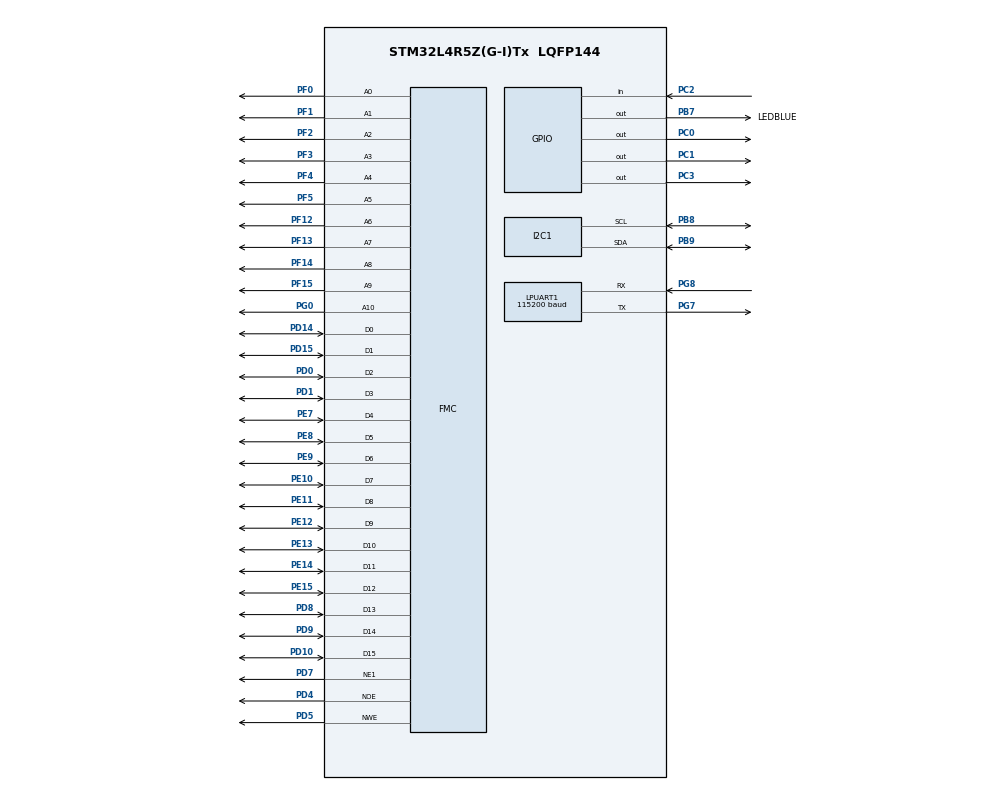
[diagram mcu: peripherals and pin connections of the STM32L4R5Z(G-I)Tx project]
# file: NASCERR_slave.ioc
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FMC.WriteFifo1=FMC_WRITE_FIFO_DISABLE
FMC.WriteFifo2=FMC_WRITE_FIFO_DISABLE
FMC.WriteFifo3=FMC_WRITE_FIFO_DISABLE
FMC.WriteFifo4=FMC_WRITE_FIFO_DISABLE
FMC.WriteOperation1=FMC_WRITE_OPERATION_ENABLE
FREERTOS.Tasks01=defaultTask,24,128,StartDefaultTask,Default,NULL,Dynamic,NULL,NULL
I2C1.OwnAddress=0x55
I2C1.Timing=0x00100D14
IWDG.Prescaler=IWDG_PRESCALER_64
IWDG.Reload=500
LPUART1.BaudRate=115200
LPUART1.WordLength=UART_WORDLENGTH_8B
Mcu.Family=STM32L4
Mcu.Name=STM32L4R5Z(G-I)Tx
Mcu.Package=LQFP144
NVIC.I2C1_ER_IRQn=true\:5\:0\:false\:false\:true\:true\:true\:true\:true
NVIC.I2C1_EV_IRQn=true\:5\:0\:false\:false\:true\:true\:true\:true\:true
NVIC.PriorityGroup=NVIC_PRIORITYGROUP_4
PB7.GPIO_Label=LEDBLUE
PB7.Signal=GPIO_Output
PB8.GPIO_Pu=GPIO_PULLUP
PB8.Mode=I2C
PB8.Signal=I2C1_SCL
PB9.GPIO_Pu=GPIO_PULLUP
PB9.Mode=I2C
PB9.Signal=I2C1_SDA
PC0.Signal=GPIO_Output
PC1.Signal=GPIO_Output
PC2.GPIO_PuPd=GPIO_PULLUP
PC2.Signal=GPIO_Input
PC3.GPIO_PuPd=GPIO_PULLDOWN
PC3.Signal=GPIO_Output
PD0.Signal=FMC_D2_DA2
PD1.Signal=FMC_D3_DA3
PD10.Signal=FMC_D15_DA15
PD14.Signal=FMC_D0_DA0
PD15.Signal=FMC_D1_DA1
PD4.Signal=FMC_NOE
PD5.Signal=FMC_NWE
PD7.Mode=NorPsramChipSelect1_1
PD7.Signal=FMC_NE1
PD8.Signal=FMC_D13_DA13
PD9.Signal=FMC_D14_DA14
PE10.Signal=FMC_D7_DA7
PE11.Signal=FMC_D8_DA8
PE12.Signal=FMC_D9_DA9
PE13.Signal=FMC_D10_DA10
PE14.Signal=FMC_D11_DA11
PE15.Signal=FMC_D12_DA12
PE7.Signal=FMC_D4_DA4
PE8.Signal=FMC_D5_DA5
PE9.Signal=FMC_D6_DA6
PF0.Signal=FMC_A0
PF1.Signal=FMC_A1
PF12.Signal=FMC_A6
PF13.Signal=FMC_A7
PF14.Signal=FMC_A8
PF15.Signal=FMC_A9
PF2.Signal=FMC_A2
PF3.Signal=FMC_A3
PF4.Signal=FMC_A4
PF5.Signal=FMC_A5
PG0.Signal=FMC_A10
PG7.Mode=Asynchronous
PG7.Signal=LPUART1_TX
PG8.Mode=Asynchronous
PG8.Signal=LPUART1_RX
ProjectManager.HeapSize=0x200
ProjectManager.StackSize=0x400
ProjectManager.TargetToolchain=STM32CubeIDE
RCC.HSE_VALUE=8000000
RCC.HSI48_VALUE=48000000
RCC.HSI_VALUE=16000000
RCC.LSE_VALUE=32768
RCC.MSI_VALUE=4000000
RCC.VCOOutputFreq_Value=32000000
SH.FMC_A0.0=FMC_A0,11b-a1
SH.FMC_A1.0=FMC_A1,11b-a1
SH.FMC_A10.0=FMC_A10,11b-a1
SH.FMC_A2.0=FMC_A2,11b-a1
SH.FMC_A3.0=FMC_A3,11b-a1
SH.FMC_A4.0=FMC_A4,11b-a1
SH.FMC_A5.0=FMC_A5,11b-a1
SH.FMC_A6.0=FMC_A6,11b-a1
SH.FMC_A7.0=FMC_A7,11b-a1
SH.FMC_A8.0=FMC_A8,11b-a1
SH.FMC_A9.0=FMC_A9,11b-a1
SH.FMC_D0_DA0.0=FMC_D0,16b-d1
SH.FMC_D10_DA10.0=FMC_D10,16b-d1
SH.FMC_D11_DA11.0=FMC_D11,16b-d1
SH.FMC_D12_DA12.0=FMC_D12,16b-d1
SH.FMC_D13_DA13.0=FMC_D13,16b-d1
SH.FMC_D14_DA14.0=FMC_D14,16b-d1
SH.FMC_D15_DA15.0=FMC_D15,16b-d1
SH.FMC_D1_DA1.0=FMC_D1,16b-d1
SH.FMC_D2_DA2.0=FMC_D2,16b-d1
SH.FMC_D3_DA3.0=FMC_D3,16b-d1
SH.FMC_D4_DA4.0=FMC_D4,16b-d1
SH.FMC_D5_DA5.0=FMC_D5,16b-d1
SH.FMC_D6_DA6.0=FMC_D6,16b-d1
SH.FMC_D7_DA7.0=FMC_D7,16b-d1
SH.FMC_D8_DA8.0=FMC_D8,16b-d1
SH.FMC_D9_DA9.0=FMC_D9,16b-d1
SH.FMC_NOE.0=FMC_NOE,Sram1
SH.FMC_NWE.0=FMC_NWE,Sram1
VP_FREERTOS_VS_CMSIS_V2.Mode=CMSIS_V2
VP_IWDG_VS_IWDG.Mode=IWDG_Activate
board=custom

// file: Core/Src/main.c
/* USER CODE BEGIN Header */
/**
  ******************************************************************************
  * @file           : main.c
  * @brief          : Main program body
  ******************************************************************************
  * @attention
  *
  * Copyright (c) 2024 STMicroelectronics.
  * All rights reserved.
  *
  * This software is licensed under terms that can be found in the LICENSE file
  * in the root directory of this software component.
  * If no LICENSE file comes with this software, it is provided AS-IS.
  *
  ******************************************************************************
  */
/* USER CODE END Header */
#include "main.h"
#include "cmsis_os.h"

/* USER CODE BEGIN Includes */
#include "NASCERR_Tasks.h"
#include "i2c_slave.h"

/* USER CODE END Includes */

I2C_HandleTypeDef hi2c1;

IWDG_HandleTypeDef hiwdg;

UART_HandleTypeDef hlpuart1;

SRAM_HandleTypeDef hsram1;

/* Definitions for defaultTask */
osThreadId_t defaultTaskHandle;
const osThreadAttr_t defaultTask_attributes = {
  .name = "defaultTask",
  .stack_size = 128 * 4,
  .priority = (osPriority_t) osPriorityNormal,
};

void SystemClock_Config(void);
static void MX_GPIO_Init(void);
static void MX_I2C1_Init(void);
static void MX_FMC_Init(void);
static void MX_LPUART1_UART_Init(void);
static void MX_IWDG_Init(void);
void StartDefaultTask(void *argument);

/* USER CODE BEGIN 0 */
int _write(int file, char *ptr, int len)
{
	if(file == 1) HAL_UART_Transmit(&hlpuart1, (uint8_t*) ptr, len, 1000);

	return len;
}
/* USER CODE END 0 */

int main(void)
{

  /* MCU Configuration--------------------------------------------------------*/

  /* Reset of all peripherals, Initializes the Flash interface and the Systick. */
  HAL_Init();

  /* Configure the system clock */
  SystemClock_Config();

  /* Initialize all configured peripherals */
  MX_GPIO_Init();
  MX_I2C1_Init();
  MX_FMC_Init();
  MX_LPUART1_UART_Init();
#if !SOFTWARE_DEBUG
  MX_IWDG_Init();
#endif
  /* USER CODE BEGIN 2 */
  i2c_slave_init();
  /* USER CODE END 2 */

  /* Init scheduler */
  osKernelInitialize();

  /* Create the thread(s) */
  /* creation of defaultTask */
//  defaultTaskHandle = osThreadNew(StartDefaultTask, NULL, &defaultTask_attributes);

  /* USER CODE BEGIN RTOS_THREADS */
  /* add threads, ... */
  defaultTaskHandle = osThreadNew(receive_dataResp, NULL, NULL);
  /* USER CODE END RTOS_THREADS */

  /* USER CODE BEGIN RTOS_EVENTS */
  /* add events, ... */
  printf("NASCER Slave application...\r\n");
  /* USER CODE END RTOS_EVENTS */

  /* Start scheduler */
  osKernelStart();

  /* We should never get here as control is now taken by the scheduler */

  /* Infinite loop */
  while (1)
  {

  }
}

void SystemClock_Config(void)
{
  RCC_OscInitTypeDef RCC_OscInitStruct = {0};
  RCC_ClkInitTypeDef RCC_ClkInitStruct = {0};

  /** Configure the main internal regulator output voltage
  */
  if (HAL_PWREx_ControlVoltageScaling(PWR_REGULATOR_VOLTAGE_SCALE1) != HAL_OK)
  {
    Error_Handler();
  }

  /** Initializes the RCC Oscillators according to the specified parameters
  * in the RCC_OscInitTypeDef structure.
  */
  RCC_OscInitStruct.OscillatorType = RCC_OSCILLATORTYPE_LSI|RCC_OSCILLATORTYPE_MSI;
  RCC_OscInitStruct.LSIState = RCC_LSI_ON;
  RCC_OscInitStruct.MSIState = RCC_MSI_ON;
  RCC_OscInitStruct.MSICalibrationValue = 0;
  RCC_OscInitStruct.MSIClockRange = RCC_MSIRANGE_6;
  RCC_OscInitStruct.PLL.PLLState = RCC_PLL_NONE;
  if (HAL_RCC_OscConfig(&RCC_OscInitStruct) != HAL_OK)
  {
    Error_Handler();
  }

  /** Initializes the CPU, AHB and APB buses clocks
  */
  RCC_ClkInitStruct.ClockType = RCC_CLOCKTYPE_HCLK|RCC_CLOCKTYPE_SYSCLK
                              |RCC_CLOCKTYPE_PCLK1|RCC_CLOCKTYPE_PCLK2;
  RCC_ClkInitStruct.SYSCLKSource = RCC_SYSCLKSOURCE_MSI;
  RCC_ClkInitStruct.AHBCLKDivider = RCC_SYSCLK_DIV1;
  RCC_ClkInitStruct.APB1CLKDivider = RCC_HCLK_DIV1;
  RCC_ClkInitStruct.APB2CLKDivider = RCC_HCLK_DIV1;

  if (HAL_RCC_ClockConfig(&RCC_ClkInitStruct, FLASH_LATENCY_0) != HAL_OK)
  {
    Error_Handler();
  }
}

static void MX_I2C1_Init(void)
{

  hi2c1.Instance = I2C1;
  hi2c1.Init.Timing = 0x00100D14;
  hi2c1.Init.OwnAddress1 = 170;
  hi2c1.Init.AddressingMode = I2C_ADDRESSINGMODE_7BIT;
  hi2c1.Init.DualAddressMode = I2C_DUALADDRESS_DISABLE;
  hi2c1.Init.OwnAddress2 = 0;
  hi2c1.Init.OwnAddress2Masks = I2C_OA2_NOMASK;
  hi2c1.Init.GeneralCallMode = I2C_GENERALCALL_DISABLE;
  hi2c1.Init.NoStretchMode = I2C_NOSTRETCH_DISABLE;
  if (HAL_I2C_Init(&hi2c1) != HAL_OK)
  {
    Error_Handler();
  }

  /** Configure Analogue filter
  */
  if (HAL_I2CEx_ConfigAnalogFilter(&hi2c1, I2C_ANALOGFILTER_ENABLE) != HAL_OK)
  {
    Error_Handler();
  }

  /** Configure Digital filter
  */
  if (HAL_I2CEx_ConfigDigitalFilter(&hi2c1, 0) != HAL_OK)
  {
    Error_Handler();
  }

}

static void MX_IWDG_Init(void)
{

  hiwdg.Instance = IWDG;
  hiwdg.Init.Prescaler = IWDG_PRESCALER_64;
  hiwdg.Init.Window = 4095;
  hiwdg.Init.Reload = 500;
  if (HAL_IWDG_Init(&hiwdg) != HAL_OK)
  {
    Error_Handler();
  }

}

static void MX_LPUART1_UART_Init(void)
{

  hlpuart1.Instance = LPUART1;
  hlpuart1.Init.BaudRate = 115200;
  hlpuart1.Init.WordLength = UART_WORDLENGTH_8B;
  hlpuart1.Init.StopBits = UART_STOPBITS_1;
  hlpuart1.Init.Parity = UART_PARITY_NONE;
  hlpuart1.Init.Mode = UART_MODE_TX_RX;
  hlpuart1.Init.HwFlowCtl = UART_HWCONTROL_NONE;
  hlpuart1.Init.OneBitSampling = UART_ONE_BIT_SAMPLE_DISABLE;
  hlpuart1.Init.ClockPrescaler = UART_PRESCALER_DIV1;
  hlpuart1.AdvancedInit.AdvFeatureInit = UART_ADVFEATURE_NO_INIT;
  hlpuart1.FifoMode = UART_FIFOMODE_DISABLE;
  if (HAL_UART_Init(&hlpuart1) != HAL_OK)
  {
    Error_Handler();
  }
  if (HAL_UARTEx_SetTxFifoThreshold(&hlpuart1, UART_TXFIFO_THRESHOLD_1_8) != HAL_OK)
  {
    Error_Handler();
  }
  if (HAL_UARTEx_SetRxFifoThreshold(&hlpuart1, UART_RXFIFO_THRESHOLD_1_8) != HAL_OK)
  {
    Error_Handler();
  }
  if (HAL_UARTEx_DisableFifoMode(&hlpuart1) != HAL_OK)
  {
    Error_Handler();
  }

}

/* FMC initialization function */
static void MX_FMC_Init(void)
{

  FMC_NORSRAM_TimingTypeDef Timing = {0};

  /** Perform the SRAM1 memory initialization sequence
  */
  hsram1.Instance = FMC_NORSRAM_DEVICE;
  hsram1.Extended = FMC_NORSRAM_EXTENDED_DEVICE;
  /* hsram1.Init */
  hsram1.Init.NSBank = FMC_NORSRAM_BANK1;
  hsram1.Init.DataAddressMux = FMC_DATA_ADDRESS_MUX_DISABLE;
  hsram1.Init.MemoryType = FMC_MEMORY_TYPE_SRAM;
  hsram1.Init.MemoryDataWidth = FMC_NORSRAM_MEM_BUS_WIDTH_16;
  hsram1.Init.BurstAccessMode = FMC_BURST_ACCESS_MODE_DISABLE;
  hsram1.Init.WaitSignalPolarity = FMC_WAIT_SIGNAL_POLARITY_LOW;
  hsram1.Init.WaitSignalActive = FMC_WAIT_TIMING_BEFORE_WS;
  hsram1.Init.WriteOperation = FMC_WRITE_OPERATION_ENABLE;
  hsram1.Init.WaitSignal = FMC_WAIT_SIGNAL_DISABLE;
  hsram1.Init.ExtendedMode = FMC_EXTENDED_MODE_DISABLE;
  hsram1.Init.AsynchronousWait = FMC_ASYNCHRONOUS_WAIT_DISABLE;
  hsram1.Init.WriteBurst = FMC_WRITE_BURST_DISABLE;
  hsram1.Init.ContinuousClock = FMC_CONTINUOUS_CLOCK_SYNC_ONLY;
  hsram1.Init.WriteFifo = FMC_WRITE_FIFO_DISABLE;
  hsram1.Init.NBLSetupTime = 0;
  hsram1.Init.PageSize = FMC_PAGE_SIZE_NONE;
  /* Timing */
  Timing.AddressSetupTime = 15;
  Timing.AddressHoldTime = 15;
  Timing.DataSetupTime = 255;
  Timing.DataHoldTime = 0;
  Timing.BusTurnAroundDuration = 15;
  Timing.CLKDivision = 16;
  Timing.DataLatency = 17;
  Timing.AccessMode = FMC_ACCESS_MODE_A;
  /* ExtTiming */

  if (HAL_SRAM_Init(&hsram1, &Timing, NULL) != HAL_OK)
  {
    Error_Handler( );
  }

}

static void MX_GPIO_Init(void)
{
  GPIO_InitTypeDef GPIO_InitStruct = {0};

  /* GPIO Ports Clock Enable */
  __HAL_RCC_GPIOF_CLK_ENABLE();
  __HAL_RCC_GPIOC_CLK_ENABLE();
  __HAL_RCC_GPIOG_CLK_ENABLE();
  __HAL_RCC_GPIOE_CLK_ENABLE();
  __HAL_RCC_GPIOD_CLK_ENABLE();
  HAL_PWREx_EnableVddIO2();
  __HAL_RCC_GPIOB_CLK_ENABLE();

  /*Configure GPIO pin Output Level */
  HAL_GPIO_WritePin(GPIOC, GPIO_PIN_0|GPIO_PIN_1|GPIO_PIN_3, GPIO_PIN_RESET);

  /*Configure GPIO pin Output Level */
  HAL_GPIO_WritePin(LEDBLUE_GPIO_Port, LEDBLUE_Pin, GPIO_PIN_RESET);

  /*Configure GPIO pins : PC0 PC1 */
  GPIO_InitStruct.Pin = GPIO_PIN_0|GPIO_PIN_1;
  GPIO_InitStruct.Mode = GPIO_MODE_OUTPUT_PP;
  GPIO_InitStruct.Pull = GPIO_NOPULL;
  GPIO_InitStruct.Speed = GPIO_SPEED_FREQ_LOW;
  HAL_GPIO_Init(GPIOC, &GPIO_InitStruct);

  /*Configure GPIO pin : PC2 */
  GPIO_InitStruct.Pin = GPIO_PIN_2;
  GPIO_InitStruct.Mode = GPIO_MODE_INPUT;
  GPIO_InitStruct.Pull = GPIO_PULLUP;
  HAL_GPIO_Init(GPIOC, &GPIO_InitStruct);

  /*Configure GPIO pin : PC3 */
  GPIO_InitStruct.Pin = GPIO_PIN_3;
  GPIO_InitStruct.Mode = GPIO_MODE_OUTPUT_PP;
  GPIO_InitStruct.Pull = GPIO_PULLDOWN;
  GPIO_InitStruct.Speed = GPIO_SPEED_FREQ_LOW;
  HAL_GPIO_Init(GPIOC, &GPIO_InitStruct);

  /*Configure GPIO pin : LEDBLUE_Pin */
  GPIO_InitStruct.Pin = LEDBLUE_Pin;
  GPIO_InitStruct.Mode = GPIO_MODE_OUTPUT_PP;
  GPIO_InitStruct.Pull = GPIO_NOPULL;
  GPIO_InitStruct.Speed = GPIO_SPEED_FREQ_LOW;
  HAL_GPIO_Init(LEDBLUE_GPIO_Port, &GPIO_InitStruct);

}

void StartDefaultTask(void *argument)
{
  for(;;)
  {
    osDelay(1);
  }
}

void Error_Handler(void)
{
  __disable_irq();
  while (1)
  {
  }
}
